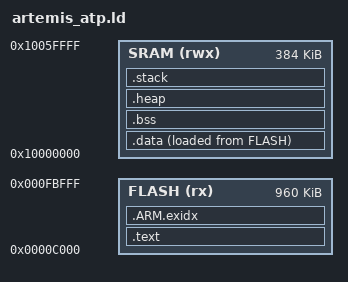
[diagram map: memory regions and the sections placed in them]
/******************************************************************************
*
* Linker script for SparkFun Artemis ATP
* 
******************************************************************************/

OUTPUT_FORMAT ("elf32-littlearm", "elf32-bigarm", "elf32-littlearm")

ENTRY(Reset_Handler)

MEMORY
{
    FLASH (rx) : ORIGIN = 0x0000C000, LENGTH = 960K
    SRAM (rwx) : ORIGIN = 0x10000000, LENGTH = 384K
}

SECTIONS
{
    .text :
    {
        . = ALIGN(4);
        KEEP(*(.isr_vector))
        *(.text*)
        *(.rodata*)
        . = ALIGN(4);
        _etext = .;
    } > FLASH

    .ARM.exidx :
    {
        __exidx_start = .;
        *(.ARM.exidx* .gnu.linkonce.armexidx.*)
        __exidx_end = .;
    } > FLASH

    .data :
    {
        . = ALIGN(4);
        _sdata = .;
        *(.data*)
        . = ALIGN(4);
        _edata = .;
    } > SRAM AT > FLASH

    _sidata = LOADADDR(.data);

    .bss :
    {
        . = ALIGN(4);
        _sbss = .;
        *(.bss*)
        *(COMMON)
        . = ALIGN(4);
        _ebss = .;
    } > SRAM

    .heap :
    {
        . = ALIGN(8);
        _sheap = .;
        . = . + 0x10000;  /* 64KB heap */
        _eheap = .;
    } > SRAM

    .stack :
    {
        . = ALIGN(8);
        _sstack = .;
        . = . + 0x4000;   /* 16KB stack */
        _estack = .;
    } > SRAM

    end = .;
}

